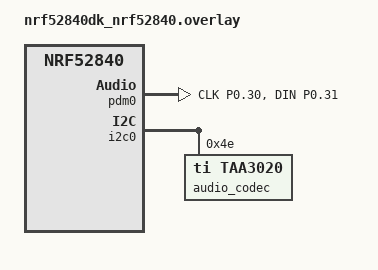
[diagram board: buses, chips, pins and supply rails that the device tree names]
/*
 * Copyright (c) 2021 Nordic Semiconductor ASA
 *
 * SPDX-License-Identifier: Apache-2.0
 */

&pinctrl {
	pdm0_default_alt: pdm0_default_alt {
		group1 {
			psels = <NRF_PSEL(PDM_CLK, 0, 30)>,
				<NRF_PSEL(PDM_DIN, 0, 31)>;
		};
	};
};

dmic_dev: &pdm0 {
	status = "okay";
	pinctrl-0 = <&pdm0_default_alt>;
	pinctrl-names = "default";
	clock-source = "PCLK32M_HFXO";
};

&i2c0 {

	audio_codec: taa3020@4e {
		status = "okay";
		compatible = "ti,taa3020";
		reg = <0x4e>;
		areg-internal-en;

		#address-cells = <1>;
		#size-cells = <0>;

		left@0 {
			compatible = "ti,taa3020-channel";
			reg = <0x0>;
			in-src = "differential";
			in-type = "line";
			impedance = "20k";
			coupling = "dc";
		};

		right@1 {
			compatible = "ti,taa3020-channel";
			reg = <0x1>;
			in-src = "differential";
			in-type = "line";
			impedance = "20k";
			coupling = "dc";
		};
	};
};
